# R7FA6E10F register map
Vendor: Renesas Electronics Corporation; Series: RA6; File version: 1.20.00
CPU: CM33 r0p4, little endian, MPU, FPU, VTOR, 4 interrupt priority bits, 96 interrupts
Registers are 8-bit, read-write, reset 0x0 unless marked. A register's access mark holds for its fields unless they carry their own. Offsets are from the block's base; [hi:lo] are bit positions.

## EDMAC0 — DMA Controller for the Ethernet Controller Channel 0
Base 0x40114000
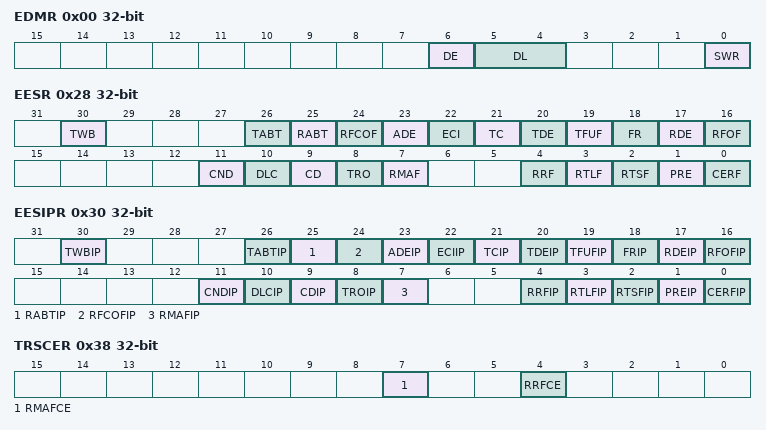
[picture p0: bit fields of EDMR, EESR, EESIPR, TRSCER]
0x00 EDMR 32-bit — EDMAC Mode Register
  [6] DE — Big Endian Mode/Little Endian Mode
    0=Big endian mode; 1=Little endian mode
  [5:4] DL — Transmit/Receive Descriptor Length
    0=16 bytes; 1=32 bytes; 2=64 bytes; 3=16 bytes
  [0] SWR — Software Reset
0x08 EDTRR 32-bit — EDMAC Transmit Request Register
  [0] TR — Transmit Request
0x10 EDRRR 32-bit — EDMAC Receive Request Register
  [0] RR — Receive Request
    0=Disable the receive function; 1=Read receive descriptor and enable the receive function
0x18 TDLAR 32-bit — Transmit Descriptor List Start Address Register
0x20 RDLAR 32-bit — Receive Descriptor List Start Address Register
0x28 EESR 32-bit — ETHERC/EDMAC Status Register
  [30] TWB — Write-Back Complete Flag
    0=Write-back not complete or no transmission requested; 1=Write-back to the transmit descriptor completed
  [26] TABT — Transmit Abort Detect Flag
    0=Frame transmission not aborted or no transmission requested; 1=Frame transmission aborted
  [25] RABT — Receive Abort Detect Flag
    0=Frame reception not aborted or no reception requested; 1=Frame reception aborted
  [24] RFCOF — Receive Frame Counter Overflow Flag
    0=Receive frame counter did not overflow; 1=Receive frame counter overflowed
  [23] ADE — Address Error Flag
    0=Invalid memory address not detected (normal operation); 1=Invalid memory address detected
  [22] ECI ro — ETHERC Status Register Source Flag
    0=ETHERC status interrupt source not detected; 1=ETHERC status interrupt source detected
  [21] TC — Frame Transfer Complete Flag
    0=Transfer not complete or no transfer requested; 1=All frames indicated in the transmit descriptor were completely transferred to the transmit FIFO
  [20] TDE — Transmit Descriptor Empty Flag
    0=EDMAC detected that the transmit descriptor valid bit (TD0.TACT) is 1; 1=EDMAC detected that the transmit descriptor valid bit (TD0.TACT) is 0
  [19] TFUF — Transmit FIFO Underflow Flag
    0=No underflow occurred; 1=Underflow occurred
  [18] FR — Frame Receive Flag
    0=Frame not received; 1=Frame received and update of the receive descriptor is complete
  [17] RDE — Receive Descriptor Empty Flag
    0=EDMAC detected that the receive descriptor valid bit (RD0.RACT) is 1; 1=EDMAC detected that the receive descriptor valid bit (RD0.RACT) is 0
  [16] RFOF — Receive FIFO Overflow Flag
    0=No overflow occurred; 1=Overflow occurred
  [11] CND — Carrier Not Detect Flag
    0=Carrier detected when transmission started; 1=Carrier not detected during preamble transmission
  [10] DLC — Loss of Carrier Detect Flag
    0=Loss of carrier not detected; 1=Loss of carrier detected during frame transmission
  [9] CD — Late Collision Detect Flag
    0=Late collision not detected; 1=Late collision detected during frame transmission
  [8] TRO — Transmit Retry Over Flag
    0=Transmit retry-over condition not detected; 1=Transmit retry-over condition detected
  [7] RMAF — Multicast Address Frame Receive Flag
    0=Multicast address frame not received; 1=Multicast address frame received
  [4] RRF — Alignment Error Flag
    0=Alignment error not detected; 1=Alignment error detected
  [3] RTLF — Frame-Too-Long Error Flag
    0=Frame-too-long error not detected; 1=Frame-too-long error detected
  [2] RTSF — Frame-Too-Short Error Flag
    0=Frame-too-short error not detected; 1=Frame-too-short error detected
  [1] PRE — PHY-LSI Receive Error Flag
    0=PHY-LSI receive error not detected; 1=PHY-LSI receive error detected
  [0] CERF — CRC Error Flag
    0=CRC error not detected; 1=CRC error detected
0x30 EESIPR 32-bit — ETHERC/EDMAC Status Interrupt Enable Register
  [30] TWBIP — Write-Back Complete Interrupt Request Enable
    0=Disable write-back complete interrupt requests; 1=Enable write-back complete interrupt requests
  [26] TABTIP — Transmit Abort Detect Interrupt Request Enable
    0=Disable transmit abort detected interrupt requests; 1=Enable transmit abort detected interrupt requests
  [25] RABTIP — Receive Abort Detect Interrupt Request Enable
    0=Disable receive abort detected interrupt requests; 1=Enable receive abort detected interrupt requests
  [24] RFCOFIP — Receive Frame Counter Overflow Interrupt Request Enable
    0=Disable receive frame counter overflow interrupt requests; 1=Enable receive frame counter overflow interrupt requests
  [23] ADEIP — Address Error Interrupt Request Enable
    0=Disable address error interrupt requests; 1=Enable address error interrupt requests
  [22] ECIIP — ETHERC Status Register Source Interrupt Request Enable
    0=Disable ETHERC status interrupt requests; 1=Enable ETHERC status interrupt requests
  [21] TCIP — Frame Transfer Complete Interrupt Request Enable
    0=Disable frame transmission complete interrupt requests; 1=Enable frame transmission complete interrupt requests
  [20] TDEIP — Transmit Descriptor Empty Interrupt Request Enable
    0=Disable transmit descriptor empty interrupt requests; 1=Enable transmit descriptor empty interrupt requests
  [19] TFUFIP — Transmit FIFO Underflow Interrupt Request Enable
    0=Disable underflow interrupt requests; 1=Enable underflow interrupt requests
  [18] FRIP — Frame Receive Interrupt Request Enable
    0=Disable frame reception interrupt requests; 1=Enable frame reception interrupt requests
  [17] RDEIP — Receive Descriptor Empty Interrupt Request Enable
    0=Disable receive descriptor empty interrupt requests; 1=Enable receive descriptor empty interrupt requests
  [16] RFOFIP — Receive FIFO Overflow Interrupt Request Enable
    0=Disable overflow interrupt requests; 1=Enable overflow interrupt requests
  [11] CNDIP — Carrier Not Detect Interrupt Request Enable
    0=Disable carrier not detected interrupt requests; 1=Enable carrier not detected interrupt requests
  [10] DLCIP — Loss of Carrier Detect Interrupt Request Enable
    0=Disable loss of carrier detected interrupt requests; 1=Enable loss of carrier detected interrupt requests
  [9] CDIP — Late Collision Detect Interrupt Request Enable
    0=Disable late collision detected interrupt requests; 1=Enable late collision detected interrupt requests
  [8] TROIP — Transmit Retry Over Interrupt Request Enable
    0=Disable transmit retry over interrupt requests; 1=Enable transmit retry over interrupt requests
  [7] RMAFIP — Multicast Address Frame Receive Interrupt Request Enable
    0=Disable multicast address frame receive interrupt requests; 1=Enable multicast address frame receive interrupt requests
  [4] RRFIP — Alignment Error Interrupt Request Enable
    0=Disable alignment error interrupt requests; 1=Enable alignment error interrupt requests
  [3] RTLFIP — Frame-Too-Long Error Interrupt Request Enable
    0=Disable frame-too-long error interrupt requests; 1=Enable frame-too-long error interrupt requests
  [2] RTSFIP — Frame-Too-Short Error Interrupt Request Enable
    0=Disable frame-too-short error interrupt requests; 1=Enable frame-too-short error interrupt requests
  [1] PREIP — PHY-LSI Receive Error Interrupt Request Enable
    0=Disable PHY-LSI receive error interrupt requests; 1=Enable PHY-LSI receive error interrupt requests
  [0] CERFIP — CRC Error Interrupt Request Enable
    0=Disable CRC error interrupt requests; 1=Enable CRC error interrupt requests
0x38 TRSCER 32-bit — ETHERC/EDMAC Transmit/Receive Status Copy Enable Register
  [7] RMAFCE — RMAF Flag Copy Enable
    0=Reflect the EESR.RMAF flag status in the RD0.RFE bit of the receive descriptor; 1=Do not reflect the EESR.RMAF flag status in the RD0.RFE bit of the receive descriptor
  [4] RRFCE — RRF Flag Copy Enable
    0=Reflect the EESR.RRF flag status in the RD0.RFE bit of the receive descriptor; 1=Do not reflect the EESR.RRF flag status in the RD0.RFE bit of the receive descriptor
0x40 RMFCR 32-bit — Missed-Frame Counter Register
  [15:0] MFC — Missed-Frame Counter
0x48 TFTR 32-bit — Transmit FIFO Threshold Register
  [10:0] TFT — Transmit FIFO Threshold
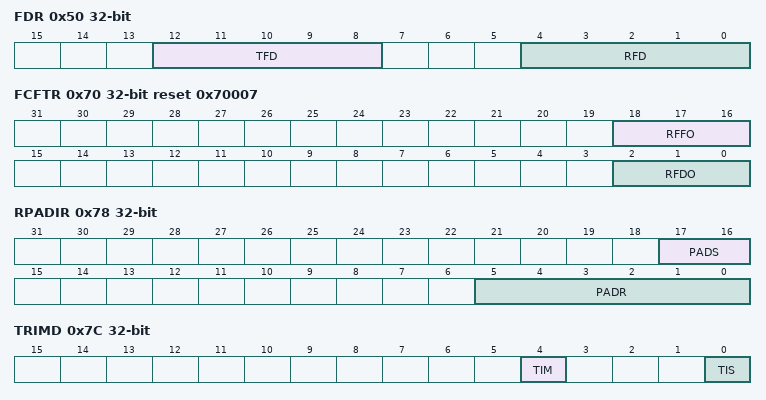
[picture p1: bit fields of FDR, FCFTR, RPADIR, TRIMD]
0x50 FDR 32-bit — FIFO Depth Register
  [12:8] TFD — Transmit FIFO Depth
    7=2048 bytes; other=Others (settings prohibited)
  [4:0] RFD — Receive FIFO Depth
    15=4096 bytes; other=Others (settings prohibited)
0x58 RMCR 32-bit — Receive Method Control Register
  [0] RNR — Receive Request Reset
    0=EDRRR.RR bit (receive request bit) is cleared to 0 when one frame is received; 1=EDRRR.RR bit (receive request bit) is not cleared to 0 when one frame is received
0x64 TFUCR 32-bit — Transmit FIFO Underflow Counter
  [15:0] UNDER — Transmit FIFO Underflow Count
0x68 RFOCR 32-bit — Receive FIFO Overflow Counter
  [15:0] OVER — Receive FIFO Overflow Count
0x6C IOSR 32-bit — Independent Output Signal Setting Register
  [0] ELB — External Loopback Mode
    0=Output low on the ET0_EXOUT pin; 1=Output high on the ET0_EXOUT pin
0x70 FCFTR 32-bit reset 0x70007 — Flow Control Start FIFO Threshold Setting Register
  [18:16] RFFO — Receive FIFO Frame PAUSE Output Threshold
  [2:0] RFDO — Receive FIFO Data PAUSE Output Threshold
0x78 RPADIR 32-bit — Receive Data Padding Insert Register
  [17:16] PADS — Padding Size
    0=Do not insert padding; other=Others (settings prohibited)
  [5:0] PADR — Padding Slot
0x7C TRIMD 32-bit — Transmit Interrupt Setting Register
  [4] TIM — Transmit Interrupt Mode
    0=Select transmission complete interrupt mode, where an interrupt occurs when a frame is transmitted; 1=Select write-back complete interrupt mode, where an interrupt occurs when write-back to the transmit descriptor is complete while the TWBI bit is 1
  [0] TIS — Transmit Interrupt Enable
    0=Disable transmit interrupts; 1=Enable transmit Interrupts
0xC8 RBWAR 32-bit ro — Receive Buffer Write Address Register
0xCC RDFAR 32-bit ro — Receive Descriptor Fetch Address Register
0xD4 TBRAR 32-bit ro — Transmit Buffer Read Address Register
0xD8 TDFAR 32-bit ro — Transmit Descriptor Fetch Address Register
